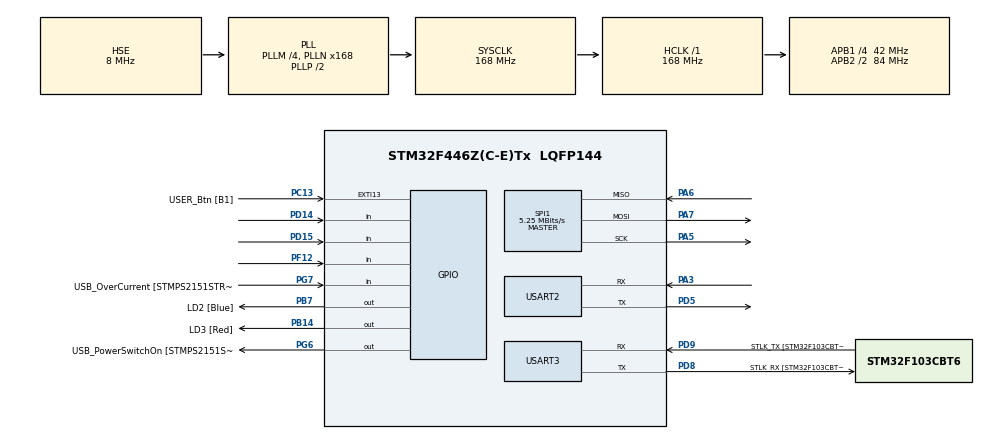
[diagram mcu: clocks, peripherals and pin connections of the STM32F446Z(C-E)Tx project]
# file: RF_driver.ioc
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FREERTOS.Tasks01=defaultTask,0,128,StartDefaultTask,Default,NULL
Mcu.Family=STM32F4
Mcu.Name=STM32F446Z(C-E)Tx
Mcu.Package=LQFP144
NVIC.PriorityGroup=NVIC_PRIORITYGROUP_4
NVIC.TIM1_UP_TIM10_IRQn=true\:0\:0\:false\:false\:true\:false\:false\:true
NVIC.TimeBase=TIM1_UP_TIM10_IRQn
NVIC.TimeBaseIP=TIM1
PA10.GPIO_Label=USB_ID
PA10.Signal=USB_OTG_FS_ID
PA11.GPIO_Label=USB_DM
PA11.Signal=USB_OTG_FS_DM
PA12.GPIO_Label=USB_DP
PA12.Signal=USB_OTG_FS_DP
PA13.GPIO_Label=TMS
PA13.Mode=Serial_Wire
PA13.Signal=SYS_JTMS-SWDIO
PA14.GPIO_Label=TCK
PA14.Mode=Serial_Wire
PA14.Signal=SYS_JTCK-SWCLK
PA3.Mode=Asynchronous
PA3.Signal=USART2_RX
PA5.Mode=Full_Duplex_Master
PA5.Signal=SPI1_SCK
PA6.Mode=Full_Duplex_Master
PA6.Signal=SPI1_MISO
PA7.Mode=Full_Duplex_Master
PA7.Signal=SPI1_MOSI
PA8.GPIO_Label=USB_SOF [TP1]
PA8.Signal=USB_OTG_FS_SOF
PA9.GPIO_Label=USB_VBUS
PA9.Signal=USB_OTG_FS_VBUS
PB14.GPIO_Label=LD3 [Red]
PB14.Signal=GPIO_Output
PB7.GPIO_Label=LD2 [Blue]
PB7.Signal=GPIO_Output
PC13.GPIO_Label=USER_Btn [B1]
PC13.Signal=GPXTI13
PC14-OSC32_IN.Mode=LSE-External-Oscillator
PC14-OSC32_IN.Signal=RCC_OSC32_IN
PC15-OSC32_OUT.Mode=LSE-External-Oscillator
PC15-OSC32_OUT.Signal=RCC_OSC32_OUT
PD14.Signal=GPIO_Input
PD15.Signal=GPIO_Input
PD5.Mode=Asynchronous
PD5.Signal=USART2_TX
PD8.GPIO_Label=STLK_RX [STM32F103CBT6_PA3]
PD8.Mode=Asynchronous
PD8.Signal=USART3_TX
PD9.GPIO_Label=STLK_TX [STM32F103CBT6_PA2]
PD9.Mode=Asynchronous
PD9.Signal=USART3_RX
PF12.Signal=GPIO_Input
PG6.GPIO_Label=USB_PowerSwitchOn [STMPS2151STR_EN]
PG6.Signal=GPIO_Output
PG7.GPIO_Label=USB_OverCurrent [STMPS2151STR_FAULT]
PG7.Signal=GPIO_Input
PH0-OSC_IN.GPIO_Label=MCO [STM32F103CBT6_PA8]
PH0-OSC_IN.Mode=HSE-External-Clock-Source
PH0-OSC_IN.Signal=RCC_OSC_IN
PH1-OSC_OUT.Mode=HSE-External-Clock-Source
PH1-OSC_OUT.Signal=RCC_OSC_OUT
ProjectManager.HeapSize=0x200
ProjectManager.StackSize=0x400
ProjectManager.TargetToolchain=SW4STM32
RCC.48MHZClocksFreq_Value=24000000
RCC.AHBFreq_Value=168000000
RCC.APB1CLKDivider=RCC_HCLK_DIV4
RCC.APB1Freq_Value=42000000
RCC.APB1TimFreq_Value=84000000
RCC.APB2CLKDivider=RCC_HCLK_DIV2
RCC.APB2Freq_Value=84000000
RCC.APB2TimFreq_Value=168000000
RCC.CortexFreq_Value=168000000
RCC.HCLKFreq_Value=168000000
RCC.HSE_VALUE=8000000
RCC.HSI_VALUE=16000000
RCC.PLLM=4
RCC.PLLMUL=RCC_PLL_MUL9
RCC.PLLN=168
RCC.PLLQ=7
RCC.PLLSourceVirtual=RCC_PLLSOURCE_HSE
RCC.PRESCALERUSB=RCC_USBCLKSOURCE_PLL_DIV1_5
RCC.SYSCLKFreq_VALUE=168000000
RCC.SYSCLKSource=RCC_SYSCLKSOURCE_PLLCLK
RCC.SYSCLKSourceVirtual=RCC_SYSCLKSOURCE_PLLCLK
RCC.USBFreq_Value=48000000
RCC.VCOOutputFreq_Value=336000000
SPI1.BaudRatePrescaler=SPI_BAUDRATEPRESCALER_16
SPI1.CalculateBaudRate=5.25 MBits/s
SPI1.Direction=SPI_DIRECTION_2LINES
SPI1.Mode=SPI_MODE_MASTER
SPI1.VirtualType=VM_MASTER
USART2.VirtualMode=VM_ASYNC
USART3.VirtualMode=VM_ASYNC
VP_FREERTOS_VS_CMSIS_V1.Mode=CMSIS_V1
VP_SYS_VS_tim1.Mode=TIM1
board=NUCLEO-F446ZE

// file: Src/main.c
/* USER CODE BEGIN Header */
/**
  ******************************************************************************
  * @file           : main.c
  * @brief          : Main program body
  ******************************************************************************
  * @attention
  *
  * <h2><center>&copy; Copyright (c) 2019 STMicroelectronics.
  * All rights reserved.</center></h2>
  *
  * This software component is licensed by ST under Ultimate Liberty license
  * SLA0044, the "License"; You may not use this file except in compliance with
  * the License. You may obtain a copy of the License at:
  *                             www.st.com/SLA0044
  *
  ******************************************************************************
  */
/* USER CODE END Header */

#include "main.h"
#include "cmsis_os.h"

/* USER CODE BEGIN Includes */
#include "rf_driver.h"

/* USER CODE END Includes */

SPI_HandleTypeDef hspi1;

UART_HandleTypeDef huart2;
UART_HandleTypeDef huart3;

osThreadId defaultTaskHandle;

void SystemClock_Config(void);
static void MX_GPIO_Init(void);
static void MX_SPI1_Init(void);
static void MX_USART3_UART_Init(void);
static void MX_USART2_UART_Init(void);
void StartDefaultTask(void const * argument);

int main(void)
{

  /* MCU Configuration--------------------------------------------------------*/

  /* Reset of all peripherals, Initializes the Flash interface and the Systick. */
  HAL_Init();

  /* Configure the system clock */
  SystemClock_Config();

  /* Initialize all configured peripherals */
  MX_GPIO_Init();
  MX_SPI1_Init();
  MX_USART3_UART_Init();
  MX_USART2_UART_Init();
  /* USER CODE BEGIN 2 */
  printf("#####################\n\r");
  init_led();
  //Init rf driver
  rf_begin(&hspi1, &huart3, OOK_4_8_kb, MHz434);

  //check if idle
  uint8_t result = rf_read_register(MARCSTATE);
  printf("result %#02x\r\n", result);

  uint8_t data[6] = {0x07,0x07,0x07,0x07,0x07,0x07};
  while(1){
  rf_write_data(TXFIFO, data, 6);
  transmit();
  }
  /* USER CODE END 2 */

  /* Create the thread(s) */
  /* definition and creation of defaultTask */
  osThreadDef(defaultTask, StartDefaultTask, osPriorityNormal, 0, 128);
  defaultTaskHandle = osThreadCreate(osThread(defaultTask), NULL);

  /* USER CODE BEGIN RTOS_THREADS */
  /* add threads, ... */
  //xTaskCreate(toggle_led, "toggle_led", 100, NULL, 2, NULL);
  /* USER CODE END RTOS_THREADS */

  /* Start scheduler */
  osKernelStart();

  /* We should never get here as control is now taken by the scheduler */

  /* Infinite loop */
  while (1)
  {

  }
}

void SystemClock_Config(void)
{
  RCC_OscInitTypeDef RCC_OscInitStruct = {0};
  RCC_ClkInitTypeDef RCC_ClkInitStruct = {0};

  /** Configure the main internal regulator output voltage
  */
  __HAL_RCC_PWR_CLK_ENABLE();
  __HAL_PWR_VOLTAGESCALING_CONFIG(PWR_REGULATOR_VOLTAGE_SCALE1);
  /** Initializes the CPU, AHB and APB busses clocks
  */
  RCC_OscInitStruct.OscillatorType = RCC_OSCILLATORTYPE_HSE;
  RCC_OscInitStruct.HSEState = RCC_HSE_BYPASS;
  RCC_OscInitStruct.PLL.PLLState = RCC_PLL_ON;
  RCC_OscInitStruct.PLL.PLLSource = RCC_PLLSOURCE_HSE;
  RCC_OscInitStruct.PLL.PLLM = 4;
  RCC_OscInitStruct.PLL.PLLN = 168;
  RCC_OscInitStruct.PLL.PLLP = RCC_PLLP_DIV2;
  RCC_OscInitStruct.PLL.PLLQ = 7;
  RCC_OscInitStruct.PLL.PLLR = 2;
  if (HAL_RCC_OscConfig(&RCC_OscInitStruct) != HAL_OK)
  {
    Error_Handler();
  }
  /** Initializes the CPU, AHB and APB busses clocks
  */
  RCC_ClkInitStruct.ClockType = RCC_CLOCKTYPE_HCLK|RCC_CLOCKTYPE_SYSCLK
                              |RCC_CLOCKTYPE_PCLK1|RCC_CLOCKTYPE_PCLK2;
  RCC_ClkInitStruct.SYSCLKSource = RCC_SYSCLKSOURCE_PLLCLK;
  RCC_ClkInitStruct.AHBCLKDivider = RCC_SYSCLK_DIV1;
  RCC_ClkInitStruct.APB1CLKDivider = RCC_HCLK_DIV4;
  RCC_ClkInitStruct.APB2CLKDivider = RCC_HCLK_DIV2;

  if (HAL_RCC_ClockConfig(&RCC_ClkInitStruct, FLASH_LATENCY_5) != HAL_OK)
  {
    Error_Handler();
  }
}

static void MX_SPI1_Init(void)
{

  /* SPI1 parameter configuration*/
  hspi1.Instance = SPI1;
  hspi1.Init.Mode = SPI_MODE_MASTER;
  hspi1.Init.Direction = SPI_DIRECTION_2LINES;
  hspi1.Init.DataSize = SPI_DATASIZE_8BIT;
  hspi1.Init.CLKPolarity = SPI_POLARITY_LOW;
  hspi1.Init.CLKPhase = SPI_PHASE_1EDGE;
  hspi1.Init.NSS = SPI_NSS_SOFT;
  hspi1.Init.BaudRatePrescaler = SPI_BAUDRATEPRESCALER_16;
  hspi1.Init.FirstBit = SPI_FIRSTBIT_MSB;
  hspi1.Init.TIMode = SPI_TIMODE_DISABLE;
  hspi1.Init.CRCCalculation = SPI_CRCCALCULATION_DISABLE;
  hspi1.Init.CRCPolynomial = 10;
  if (HAL_SPI_Init(&hspi1) != HAL_OK)
  {
    Error_Handler();
  }

}

static void MX_USART2_UART_Init(void)
{

  huart2.Instance = USART2;
  huart2.Init.BaudRate = 115200;
  huart2.Init.WordLength = UART_WORDLENGTH_8B;
  huart2.Init.StopBits = UART_STOPBITS_1;
  huart2.Init.Parity = UART_PARITY_NONE;
  huart2.Init.Mode = UART_MODE_TX_RX;
  huart2.Init.HwFlowCtl = UART_HWCONTROL_NONE;
  huart2.Init.OverSampling = UART_OVERSAMPLING_16;
  if (HAL_UART_Init(&huart2) != HAL_OK)
  {
    Error_Handler();
  }

}

static void MX_USART3_UART_Init(void)
{

  huart3.Instance = USART3;
  huart3.Init.BaudRate = 115200;
  huart3.Init.WordLength = UART_WORDLENGTH_8B;
  huart3.Init.StopBits = UART_STOPBITS_1;
  huart3.Init.Parity = UART_PARITY_NONE;
  huart3.Init.Mode = UART_MODE_TX_RX;
  huart3.Init.HwFlowCtl = UART_HWCONTROL_NONE;
  huart3.Init.OverSampling = UART_OVERSAMPLING_16;
  if (HAL_UART_Init(&huart3) != HAL_OK)
  {
    Error_Handler();
  }

}

static void MX_GPIO_Init(void)
{
  GPIO_InitTypeDef GPIO_InitStruct = {0};

  /* GPIO Ports Clock Enable */
  __HAL_RCC_GPIOC_CLK_ENABLE();
  __HAL_RCC_GPIOH_CLK_ENABLE();
  __HAL_RCC_GPIOA_CLK_ENABLE();
  __HAL_RCC_GPIOF_CLK_ENABLE();
  __HAL_RCC_GPIOB_CLK_ENABLE();
  __HAL_RCC_GPIOD_CLK_ENABLE();
  __HAL_RCC_GPIOG_CLK_ENABLE();

  /*Configure GPIO pin Output Level */
  HAL_GPIO_WritePin(GPIOB, LD3_Pin|LD2_Pin, GPIO_PIN_RESET);

  /*Configure GPIO pin Output Level */
  HAL_GPIO_WritePin(USB_PowerSwitchOn_GPIO_Port, USB_PowerSwitchOn_Pin, GPIO_PIN_RESET);

  /*Configure GPIO pin : USER_Btn_Pin */
  GPIO_InitStruct.Pin = USER_Btn_Pin;
  GPIO_InitStruct.Mode = GPIO_MODE_IT_RISING;
  GPIO_InitStruct.Pull = GPIO_NOPULL;
  HAL_GPIO_Init(USER_Btn_GPIO_Port, &GPIO_InitStruct);

  /*Configure GPIO pin : PF12 */
  GPIO_InitStruct.Pin = GPIO_PIN_12;
  GPIO_InitStruct.Mode = GPIO_MODE_INPUT;
  GPIO_InitStruct.Pull = GPIO_NOPULL;
  HAL_GPIO_Init(GPIOF, &GPIO_InitStruct);

  /*Configure GPIO pins : LD3_Pin LD2_Pin */
  GPIO_InitStruct.Pin = LD3_Pin|LD2_Pin;
  GPIO_InitStruct.Mode = GPIO_MODE_OUTPUT_PP;
  GPIO_InitStruct.Pull = GPIO_NOPULL;
  GPIO_InitStruct.Speed = GPIO_SPEED_FREQ_LOW;
  HAL_GPIO_Init(GPIOB, &GPIO_InitStruct);

  /*Configure GPIO pins : PD14 PD15 */
  GPIO_InitStruct.Pin = GPIO_PIN_14|GPIO_PIN_15;
  GPIO_InitStruct.Mode = GPIO_MODE_INPUT;
  GPIO_InitStruct.Pull = GPIO_NOPULL;
  HAL_GPIO_Init(GPIOD, &GPIO_InitStruct);

  /*Configure GPIO pin : USB_PowerSwitchOn_Pin */
  GPIO_InitStruct.Pin = USB_PowerSwitchOn_Pin;
  GPIO_InitStruct.Mode = GPIO_MODE_OUTPUT_PP;
  GPIO_InitStruct.Pull = GPIO_NOPULL;
  GPIO_InitStruct.Speed = GPIO_SPEED_FREQ_LOW;
  HAL_GPIO_Init(USB_PowerSwitchOn_GPIO_Port, &GPIO_InitStruct);

  /*Configure GPIO pin : USB_OverCurrent_Pin */
  GPIO_InitStruct.Pin = USB_OverCurrent_Pin;
  GPIO_InitStruct.Mode = GPIO_MODE_INPUT;
  GPIO_InitStruct.Pull = GPIO_NOPULL;
  HAL_GPIO_Init(USB_OverCurrent_GPIO_Port, &GPIO_InitStruct);

  /*Configure GPIO pins : USB_SOF_Pin USB_ID_Pin USB_DM_Pin USB_DP_Pin */
  GPIO_InitStruct.Pin = USB_SOF_Pin|USB_ID_Pin|USB_DM_Pin|USB_DP_Pin;
  GPIO_InitStruct.Mode = GPIO_MODE_AF_PP;
  GPIO_InitStruct.Pull = GPIO_NOPULL;
  GPIO_InitStruct.Speed = GPIO_SPEED_FREQ_VERY_HIGH;
  GPIO_InitStruct.Alternate = GPIO_AF10_OTG_FS;
  HAL_GPIO_Init(GPIOA, &GPIO_InitStruct);

  /*Configure GPIO pin : USB_VBUS_Pin */
  GPIO_InitStruct.Pin = USB_VBUS_Pin;
  GPIO_InitStruct.Mode = GPIO_MODE_INPUT;
  GPIO_InitStruct.Pull = GPIO_NOPULL;
  HAL_GPIO_Init(USB_VBUS_GPIO_Port, &GPIO_InitStruct);

}

void StartDefaultTask(void const * argument)
{

  for(;;)
  {
    osDelay(1);
  }
}

void HAL_TIM_PeriodElapsedCallback(TIM_HandleTypeDef *htim)
{
  if (htim->Instance == TIM1) {
    HAL_IncTick();
  }
}

void Error_Handler(void)
{
}

/************************ (C) COPYRIGHT STMicroelectronics *****END OF FILE****/
